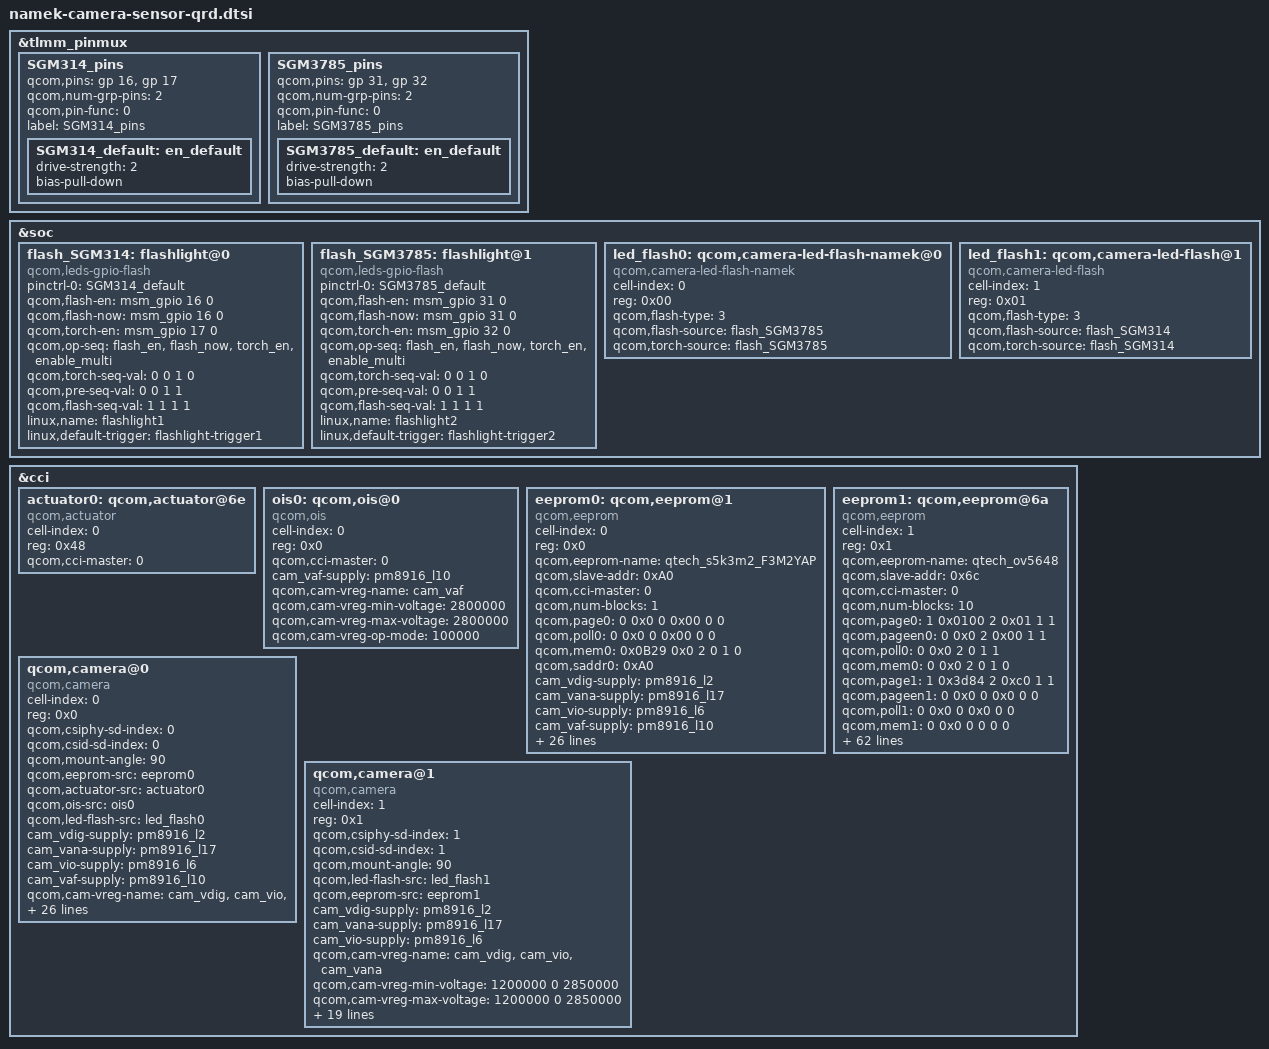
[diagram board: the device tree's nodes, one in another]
/*
 * Copyright (c) 2014, The Linux Foundation. All rights reserved.
 *
 * This program is free software; you can redistribute it and/or modify
 * it under the terms of the GNU General Public License version 2 and
 * only version 2 as published by the Free Software Foundation.
 *
 * This program is distributed in the hope that it will be useful,
 * but WITHOUT ANY WARRANTY; without even the implied warranty of
 * MERCHANTABILITY or FITNESS FOR A PARTICULAR PURPOSE.  See the
 * GNU General Public License for more details.
 */


&tlmm_pinmux {
	SGM314_pins {
		qcom,pins = <&gp 16>, <&gp 17>;
		qcom,num-grp-pins = <2>;
		qcom,pin-func = <0>;
		label = "SGM314_pins";
		SGM314_default: en_default {
			  drive-strength = <2>;
			  bias-pull-down;
		};
	};
};

&tlmm_pinmux {
	SGM3785_pins {
		qcom,pins = <&gp 31>, <&gp 32>;
		qcom,num-grp-pins = <2>;
		qcom,pin-func = <0>;
		label = "SGM3785_pins";
		SGM3785_default: en_default {
			  drive-strength = <2>;
			  bias-pull-down;
		};
	};
};

&soc {
	flash_SGM314:flashlight@0 {
		compatible = "qcom,leds-gpio-flash";
		status = "okay";
		pinctrl-names = "flash_default";
		pinctrl-0 = <&SGM314_default>;
		qcom,flash-en = <&msm_gpio 16 0>;
		qcom,flash-now = <&msm_gpio 16 0>;
		qcom,torch-en = <&msm_gpio 17 0>;
		qcom,op-seq = "flash_en", "flash_now", "torch_en", "enable_multi";
		qcom,torch-seq-val = <0 0 1 0>;
		qcom,pre-seq-val =   <0 0 1 1>;
		qcom,flash-seq-val = <1 1 1 1>;
		linux,name = "flashlight1";
		linux,default-trigger = "flashlight-trigger1";
	};

	flash_SGM3785:flashlight@1 {
		compatible = "qcom,leds-gpio-flash";
		status = "okay";
		pinctrl-names = "flash_default";
		pinctrl-0 = <&SGM3785_default>;
		qcom,flash-en = <&msm_gpio 31 0>;
		qcom,flash-now = <&msm_gpio 31 0>;
		qcom,torch-en = <&msm_gpio 32 0>;
		qcom,op-seq = "flash_en", "flash_now", "torch_en", "enable_multi";
		qcom,torch-seq-val = <0 0 1 0>;
		qcom,pre-seq-val =   <0 0 1 1>;
		qcom,flash-seq-val = <1 1 1 1>;
		linux,name = "flashlight2";
		linux,default-trigger = "flashlight-trigger2";
	};

	/delete-node/ qcom,camera-led-flash;
	led_flash0: qcom,camera-led-flash-namek@0 {
		cell-index = <0>;
		reg = <0x00>;
		compatible = "qcom,camera-led-flash-namek";
		qcom,flash-type = <3>;
		qcom,flash-source = <&flash_SGM3785>;
		qcom,torch-source = <&flash_SGM3785>;
	};

	led_flash1: qcom,camera-led-flash@1{
		cell-index = <1>;
		reg = <0x01>;
		compatible = "qcom,camera-led-flash";
		qcom,flash-type = <3>;
		qcom,flash-source = <&flash_SGM314>;
		qcom,torch-source = <&flash_SGM314>;
	};
};

&cci {
	/delete-node/ qcom,actuator@0;
	actuator0: qcom,actuator@6e {
		cell-index = <0>;
		reg = <0x48>;
		compatible = "qcom,actuator";
		qcom,cci-master = <0>;
	};

	ois0: qcom,ois@0 {
		cell-index = <0>;
		reg = <0x0>;
		compatible = "qcom,ois";
		qcom,cci-master = <0>;
		cam_vaf-supply = <&pm8916_l10>;
		qcom,cam-vreg-name = "cam_vaf";
		qcom,cam-vreg-min-voltage = <2800000>;
		qcom,cam-vreg-max-voltage = <2800000>;
		qcom,cam-vreg-op-mode = <100000>;
	};

	/delete-node/ qcom,eeprom@0;
	/delete-node/ qcom,eeprom@1;
	eeprom0: qcom,eeprom@1{
		cell-index = <0>;
		reg = <0x0>;
		qcom,eeprom-name = "qtech_s5k3m2_F3M2YAP";
		compatible = "qcom,eeprom";
		qcom,slave-addr = <0xA0>;
		qcom,cci-master = <0>;
		qcom,num-blocks = <1>;

		qcom,page0 = <0 0x0 0 0x00 0 0>;
		qcom,poll0 = <0 0x0 0 0x00 0 0>;
		qcom,mem0 = <0x0B29 0x0 2 0 1 0>;
		qcom,saddr0 = <0xA0>;
		cam_vdig-supply = <&pm8916_l2>;
		cam_vana-supply = <&pm8916_l17>;
		cam_vio-supply = <&pm8916_l6>;
		cam_vaf-supply = <&pm8916_l10>;
		qcom,cam-vreg-name = "cam_vdig", "cam_vio", "cam_vana",
			"cam_vaf";
		qcom,cam-vreg-type = <0 1 0 0>;
		qcom,cam-vreg-min-voltage = <1200000 0 2850000 2800000>;
		qcom,cam-vreg-max-voltage = <1200000 0 2850000 2800000>;
		qcom,cam-vreg-op-mode = <200000 0 80000 100000>;
		pinctrl-names = "cam_default", "cam_suspend";
		pinctrl-0 = <&cam_sensor_mclk0_default &cam_sensor_rear_default>;
		pinctrl-1 = <&cam_sensor_mclk0_sleep &cam_sensor_rear_sleep>;
		gpios = <&msm_gpio 26 0>,
                         <&msm_gpio 2 0>;
                qcom,gpio-vdig = <1>;
		qcom,gpio-req-tbl-num = <0 1>;
		qcom,gpio-req-tbl-flags = <1 0>;
		qcom,gpio-req-tbl-label = "CAMIF_MCLK",
                                          "MCAM_GPIO_IOVDD";
	        qcom,cam-power-seq-type = "sensor_gpio",
                                          "sensor_clk";
		  qcom,cam-power-seq-val = "sensor_gpio_vio",
		   "sensor_cam_mclk" ;
		  qcom,cam-power-seq-cfg-val = <1  24000000>;
		  qcom,cam-power-seq-delay = <1  10>;

		  clocks = <&clock_gcc clk_mclk0_clk_src>,
			   <&clock_gcc clk_gcc_camss_mclk0_clk>;
		clock-names = "cam_src_clk", "cam_clk";
	};

	eeprom1: qcom,eeprom@6a{
		cell-index = <1>;
		reg = <0x1>;
		qcom,eeprom-name = "qtech_ov5648";
		compatible = "qcom,eeprom";
		qcom,slave-addr = <0x6c>;
		qcom,cci-master = <0>;
		qcom,num-blocks = <10>;
		qcom,page0 = <1 0x0100 2 0x01 1 1>;
		qcom,pageen0 = <0 0x0 2 0x00 1 1>;
		qcom,poll0 = <0 0x0 2 0 1 1>;
		qcom,mem0 = <0 0x0 2 0 1 0>;

		qcom,page1 = <1 0x3d84 2 0xc0 1 1>;
		qcom,pageen1 = <0 0x0 0 0x0 0 0>;
		qcom,poll1 = <0 0x0 0 0x0 0 0>;
		qcom,mem1 = <0 0x0 0 0 0 0>;

		qcom,page2 = <1 0x3d85 2 0x00 1 1>;
		qcom,pageen2 = <0 0x0 0 0x0 0 0>;
		qcom,poll2 = <0 0x0 0 0x0 0 0>;
		qcom,mem2 = <0 0x0 0 0 0 0>;

		qcom,page3 = <1 0x3d86 2 0x0f 1 1>;
		qcom,pageen3 = <0 0x0 0 0x0 0 0>;
		qcom,poll3 = <0 0x0 0 0x0 0 0>;
		qcom,mem3 = <0 0x0 0 0 0 0>;

		qcom,page4 = <1 0x3d81 2 0x01 1 5>;
		qcom,pageen4 = <0 0x0 0 0x0 0 0>;
		qcom,poll4 = <0 0x0 0 0x0 0 0>;
		qcom,mem4 = <16 0x3d00 2 0 1 1>;

                qcom,page5 = <1 0x3d84 2 0xc0 1 0>;
                qcom,pageen5 = <0 0x0 0 0x0 0 0>;
                qcom,poll5 = <0 0x0 0 0x0 0 0>;
                qcom,mem5 = <0 0x0 0 0 0 0>;

                qcom,page6 = <1 0x3d85 2 0x10 1 0>;
                qcom,pageen6 = <0 0x0 0 0x0 0 0>;
                qcom,poll6 = <0 0x0 0 0x0 0 0>;
                qcom,mem6 = <0 0x0 0 0 0 0>;

                qcom,page7 = <1 0x3d86 2 0x1f 1 0>;
                qcom,pageen7 = <0 0x0 0 0x0 0 0>;
                qcom,poll7 = <0 0x0 0 0x0 0 0>;
                qcom,mem7 = <0 0x0 0 0 0 0>;

                qcom,page8 = <1 0x3d81 2 0x01 1 5>;
                qcom,pageen8 = <0 0x0 0 0x0 0 0>;
                qcom,poll8 = <0 0x0 0 0x0 0 0>;
                qcom,mem8 = <0 0x0 0 0 0 0>;

                qcom,page9 = <0 0x0 0 0x0 0 0>;
                qcom,pageen9 = <0 0x0 0 0x0 0 0>;
                qcom,poll9 = <0 0x0 0 0x0 0 0>;
                qcom,mem9 = <16 0x3d00 2 0 1 0>;

		cam_vdig-supply = <&pm8916_l2>;
		cam_vana-supply = <&pm8916_l17>;
		cam_vio-supply = <&pm8916_l6>;
		qcom,cam-vreg-name = "cam_vdig", "cam_vio", "cam_vana";
		qcom,cam-vreg-min-voltage = <1200000 0 2850000>;
		qcom,cam-vreg-max-voltage = <1200000 0 2850000>;
		qcom,cam-vreg-op-mode = <200000 0 80000>;
		pinctrl-names = "cam_default", "cam_suspend";
		pinctrl-0 = <&cam_sensor_mclk1_default &cam_sensor_front_default>;
		pinctrl-1 = <&cam_sensor_mclk1_sleep &cam_sensor_front_sleep>;
		gpios = <&msm_gpio 27 0>,
			<&msm_gpio 28 0>,
			<&msm_gpio 33 0>,
			<&msm_gpio 35 0>;
		qcom,gpio-reset = <1>;
		qcom,gpio-standby = <2>;
	    qcom,gpio-vdig = <3>;
		qcom,gpio-req-tbl-num = <0 1 2 3>;
		qcom,gpio-req-tbl-flags = <1 0 0 0>;
		qcom,gpio-req-tbl-label = "CAMIF_MCLK1",
			"SCAM_RESET",
			"SCAM_STANDBY",
			"SCAM_GPIO_DVDD";

        qcom,cam-power-seq-type = "sensor_gpio",
		   "sensor_gpio", "sensor_gpio",
		   "sensor_clk";
		qcom,cam-power-seq-val =  "sensor_gpio_vdig",
		   "sensor_gpio_reset",
		   "sensor_gpio_standby",
		   "sensor_cam_mclk" ;
		qcom,cam-power-seq-cfg-val = < 1 1 1 24000000>;
		qcom,cam-power-seq-delay = <1 10 5 10>;

		clocks = <&clock_gcc clk_mclk1_clk_src>,
			   <&clock_gcc clk_gcc_camss_mclk1_clk>;
		clock-names = "cam_src_clk", "cam_clk";
	};


	qcom,camera@0 {
		cell-index = <0>;
		compatible = "qcom,camera";
		reg = <0x0>;
		qcom,csiphy-sd-index = <0>;
		qcom,csid-sd-index = <0>;
		qcom,mount-angle = <90>;
		qcom,eeprom-src = <&eeprom0>;
		qcom,actuator-src = <&actuator0>;
		qcom,ois-src = <&ois0>;
		qcom,led-flash-src = <&led_flash0>;
		cam_vdig-supply = <&pm8916_l2>;
		cam_vana-supply = <&pm8916_l17>;
		cam_vio-supply = <&pm8916_l6>;
		cam_vaf-supply = <&pm8916_l10>;
		qcom,cam-vreg-name = "cam_vdig", "cam_vio", "cam_vana",
							"cam_vaf";
		qcom,cam-vreg-min-voltage = <1200000 0 2850000 2800000>;
		qcom,cam-vreg-max-voltage = <1200000 0 2850000 2800000>;
		qcom,cam-vreg-op-mode = <200000 0 80000 100000>;
		pinctrl-names = "cam_default", "cam_suspend";
		pinctrl-0 = <&cam_sensor_mclk0_default &cam_sensor_rear_default>;
		pinctrl-1 = <&cam_sensor_mclk0_sleep &cam_sensor_rear_sleep>;
		gpios = <&msm_gpio 26 0>,
			<&msm_gpio 34 0>,
			<&msm_gpio 2 0>,
			<&msm_gpio 36 0>,
			<&msm_gpio 52 0>;
		qcom,gpio-reset = <1>;
		qcom,gpio-af-pwdm = <2>;
		qcom,gpio-vdig = <3>;
		qcom,gpio-vana = <4>;
		qcom,gpio-req-tbl-num = <0 1 2 3 4>;
		qcom,gpio-req-tbl-flags = <1 0 0 0 0>;
		qcom,gpio-req-tbl-label = "CAMIF_MCLK0",
			"MCAM_RESET",
			"MCAM_AF_PWDM",
			"MCAM_GPIO_DVDD",
			"MCAM_GPIO_AVDD";
		qcom,sensor-position = <0>;
		qcom,sensor-mode = <0>;
		qcom,cci-master = <0>;
		status = "ok";
		clocks = <&clock_gcc clk_mclk0_clk_src>,
				<&clock_gcc clk_gcc_camss_mclk0_clk>;
		clock-names = "cam_src_clk", "cam_clk";
	};

	qcom,camera@1 {
		cell-index = <1>;
		compatible = "qcom,camera";
		reg = <0x1>;
		qcom,csiphy-sd-index = <1>;
		qcom,csid-sd-index = <1>;
		qcom,mount-angle = <90>;
		qcom,led-flash-src = <&led_flash1>;
		qcom,eeprom-src = <&eeprom1>;
		cam_vdig-supply = <&pm8916_l2>;
		cam_vana-supply = <&pm8916_l17>;
		cam_vio-supply = <&pm8916_l6>;
		qcom,cam-vreg-name = "cam_vdig", "cam_vio", "cam_vana";
		qcom,cam-vreg-min-voltage = <1200000 0 2850000>;
		qcom,cam-vreg-max-voltage = <1200000 0 2850000>;
		qcom,cam-vreg-op-mode = <200000 0 80000>;
		pinctrl-names = "cam_default", "cam_suspend";
		pinctrl-0 = <&cam_sensor_mclk1_default &cam_sensor_front_default>;
		pinctrl-1 = <&cam_sensor_mclk1_sleep &cam_sensor_front_sleep>;
		gpios = <&msm_gpio 27 0>,
			<&msm_gpio 28 0>,
			<&msm_gpio 33 0>,
			<&msm_gpio 35 0>;
		qcom,gpio-reset = <1>;
		qcom,gpio-standby = <2>;
		 qcom,gpio-vdig = <3>;
		qcom,gpio-req-tbl-num = <0 1 2 3>;
		qcom,gpio-req-tbl-flags = <1 0 0 0>;
		qcom,gpio-req-tbl-label = "CAMIF_MCLK1",
			"SCAM_RESET",
			"SCAM_STANDBY",
			"SCAM_GPIO_DVDD";
		qcom,sensor-position = <1>;
		qcom,sensor-mode = <0>;
		qcom,cci-master = <0>;
		status = "ok";
		clocks = <&clock_gcc clk_mclk1_clk_src>,
				<&clock_gcc clk_gcc_camss_mclk1_clk>;
		clock-names = "cam_src_clk", "cam_clk";
	};
};
